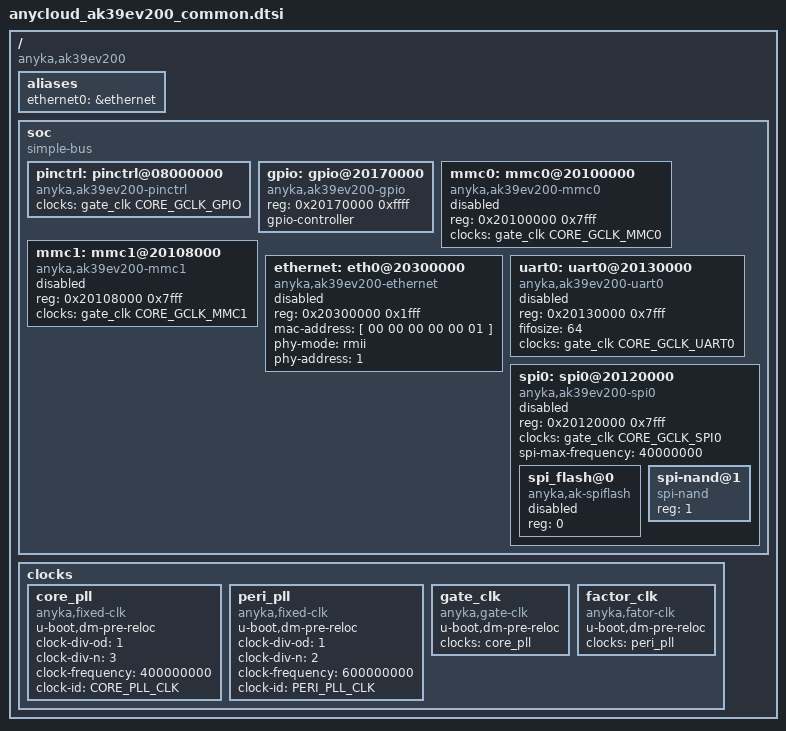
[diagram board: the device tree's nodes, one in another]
// SPDX-License-Identifier: GPL-2.0+
/*
 * Anyka39EV200 SoC device tree source
 *
 */

#include <dt-bindings/clock/ak39ev200-clock.h>
/ {
    compatible = "anyka,ak39ev200";
    #address-cells = <1>;
    #size-cells = <1>;

    aliases {
        ethernet0 = &ethernet;
        //mac_mdio0 = &mdio0;
    } ;

    soc: soc {
        compatible = "simple-bus";
        #address-cells = <1>;
        #size-cells = <1>;
        ranges;

        pinctrl: pinctrl@08000000 {
            compatible = "anyka,ak39ev200-pinctrl";
            #address-cells = <1>;
            #size-cells = <1>;
            clocks = <&gate_clk CORE_GCLK_GPIO>;
            status = "okay";
        };

        gpio: gpio@20170000 {
            compatible = "anyka,ak39ev200-gpio";
            reg = <0x20170000 0xffff>;

            /*interrupt-controller;*/
            /*#interrupt-cells = <2>;*/
            /*interrupts = <15 0>;*/
            /*clocks = <&gclk_asic ASIC_GCLK_GPIO>;*/

            gpio-controller;
            #gpio-cells = <2>;
            status = "okay";
        };

        mmc0: mmc0@20100000 {
            compatible = "anyka,ak39ev200-mmc0";
            reg = <0x20100000 0x7fff>;
            /*interrupts = <4 0>,<28 0>;*/
            clocks = <&gate_clk CORE_GCLK_MMC0>;
            status = "disable";
        };

        mmc1: mmc1@20108000 {
            compatible = "anyka,ak39ev200-mmc1";
            reg = <0x20108000 0x7fff>;
            /*interrupts = <5 0>, <28 0>;*/
            clocks = <&gate_clk CORE_GCLK_MMC1>;
            status = "disable";
        };

        ethernet: eth0@20300000 {
            compatible = "anyka,ak39ev200-ethernet";
            reg = <0x20300000 0x1fff>;
            mac-address = [ 00 00 00 00 00 01 ];
            phy-mode = "rmii";
            phy-address = <1>;

            status = "disable";
        };

        uart0: uart0@20130000 {
            compatible = "anyka,ak39ev200-uart0";
            reg = <0x20130000 0x7fff>;
            /*interrupts = <10 0>;*/
            fifosize = <64>;
            clocks = <&gate_clk CORE_GCLK_UART0>;
            status = "disable";
        };

        spi0: spi0@20120000 {
            compatible = "anyka,ak39ev200-spi0";
            reg = <0x20120000 0x7fff>;
            /*interrupts = <8 0>;*/
            clocks = <&gate_clk CORE_GCLK_SPI0>;
            clock-names = "spi0", "spi0_bus";
            spi-max-frequency = <40000000>;
            #address-cells = <1>;
            #size-cells = <0>;
            status = "disable";

            spi_flash@0 {
                compatible = "anyka,ak-spiflash";
                reg = <0>; /* Chip select 0 */
                status = "disable";
                #address-cells = <1>;
                #size-cells = <0>;
            };

            spi-nand@1 {
                #address-cells = <1>;
                #size-cells = <1>;
                compatible = "spi-nand";
                reg = <1>;
            };
        };
    };

    clocks {
        core_pll: core_pll {
            compatible = "anyka,fixed-clk";
            u-boot,dm-pre-reloc;
            #clock-cells = <0>;
            clock-div-od = <1>;
            clock-div-n = <3>;
            clock-frequency = <400000000>;
            clock-id = <CORE_PLL_CLK>;
            status = "okay";
        };

        peri_pll: peri_pll {
            compatible = "anyka,fixed-clk";
            u-boot,dm-pre-reloc;
            #clock-cells = <0>;
            clock-div-od = <1>;
            clock-div-n = <2>;
            clock-frequency = <600000000>;
            clock-id = <PERI_PLL_CLK>;
            status = "okay";
        };

        gate_clk: gate_clk {
            compatible = "anyka,gate-clk";
            u-boot,dm-pre-reloc;
            #clock-cells = <1>;
            clocks = <&core_pll>;
            status = "okay";
        };

        factor_clk: factor_clk {
            compatible = "anyka,fator-clk";
            u-boot,dm-pre-reloc;
            #clock-cells = <1>;
            clocks = <&peri_pll>;
            status = "okay";
        };
    };
};
